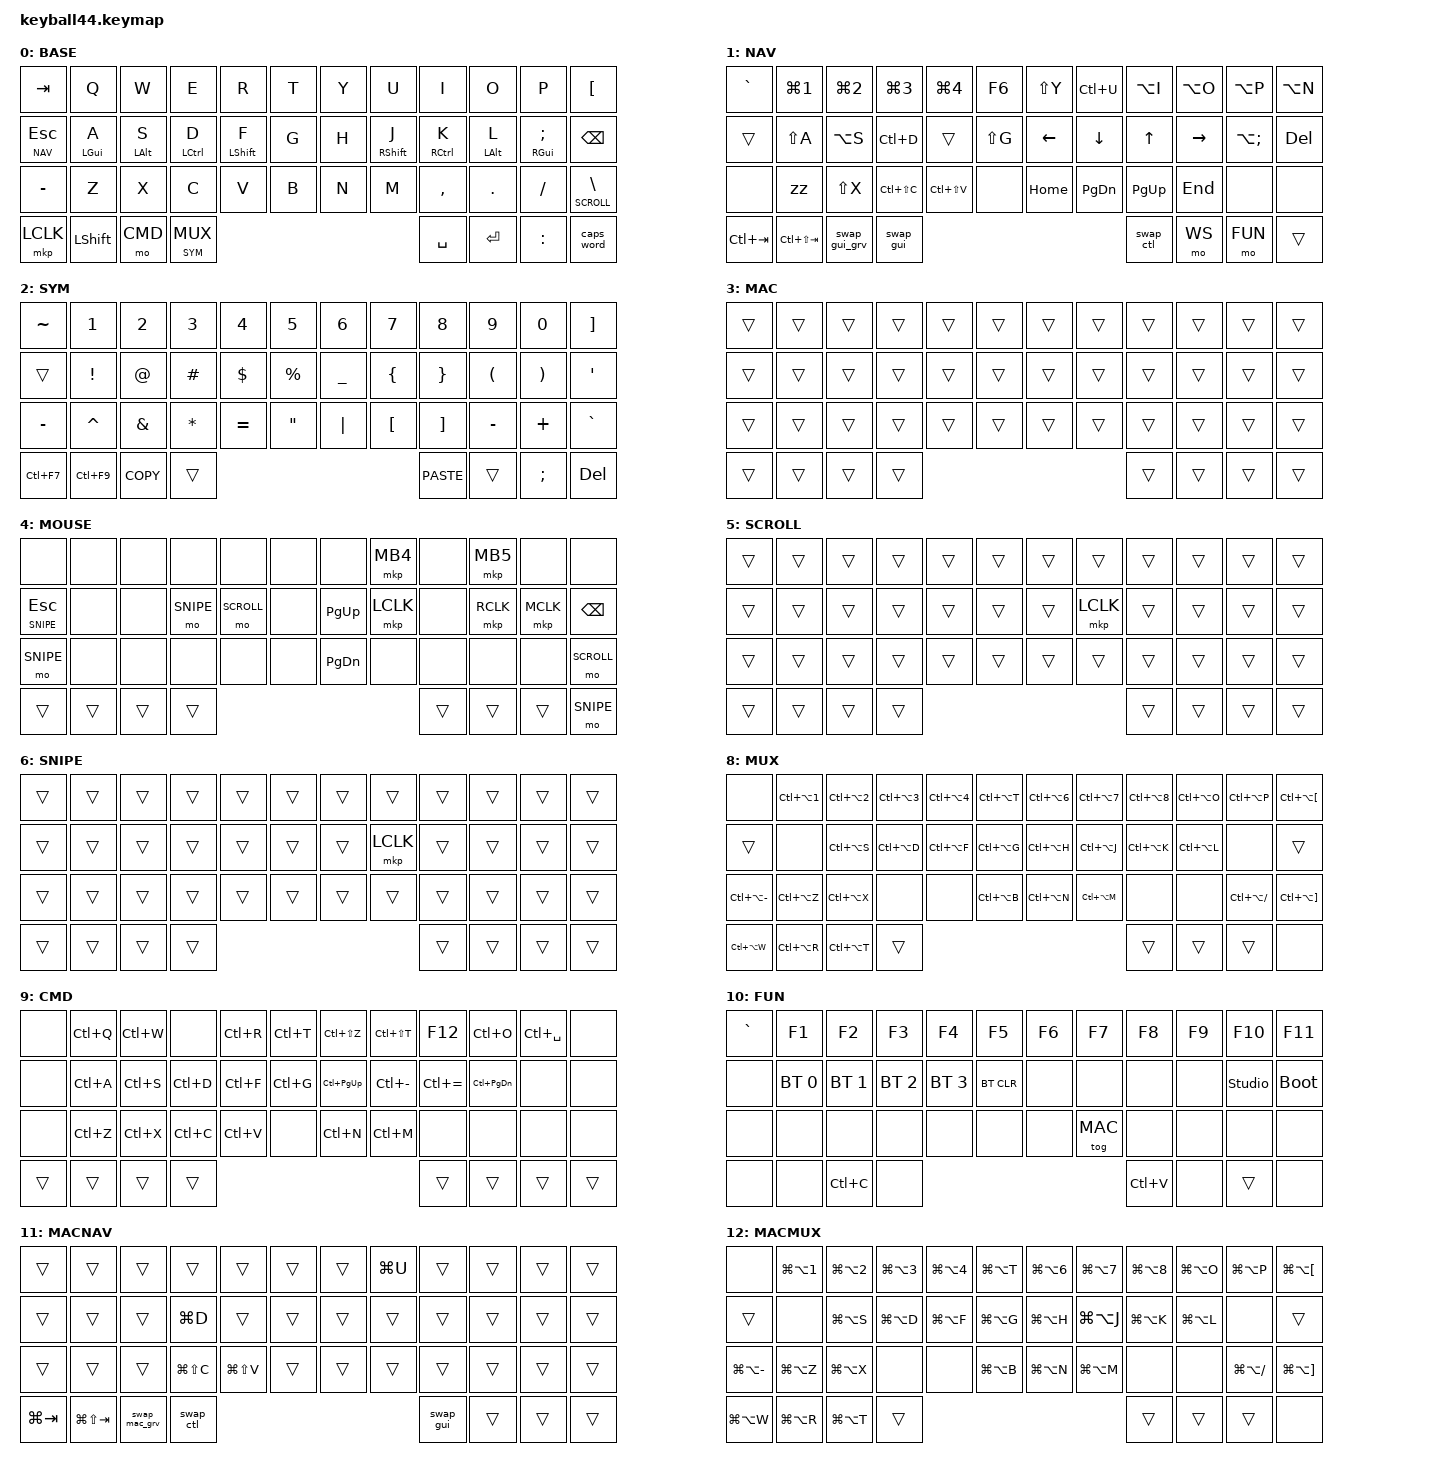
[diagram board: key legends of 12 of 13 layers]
/*
 * Keyball44 — semantic-redesign branch (mac-anchored).
 *
 * Shared with Cornix: homerow mods, sym_mux thumb (hold = SYM, tap =
 * sticky MUX, tap-then-hold = held MUX), zellij MUX layer, helix NAV
 * layer with tri-state swappers.
 *
 * ANCHOR: Linux-truth + macOS per-device modifier swap. macOS System
 * Settings > Keyboard > Modifier Keys (for THIS keyboard only) swaps
 * Ctrl <-> Cmd. Firmware emits Linux-native chords; mac receives Ctrl
 * as Cmd and Gui as Ctrl. Chords holding BOTH Ctrl and Gui are
 * swap-invariant (window quad). Ctrl-chords = command space,
 * Super-chords = window/desktop space.
 *
 * Redesign vs main:
 *   CMD (9)  — semantic command layer on the left thumb (old LCTRL slot):
 *              copy/paste/tab/find etc. as mnemonic Ctrl-chords — native
 *              on KDE, arrive as Cmd-chords on mac via the swap.
 *   WS  (7)  — old DE rebuilt: hjkl = Super+arrows (KDE: bind Meta+arrows
 *              to desktops/overview; mac receives Ctrl+arrows = native
 *              spaces/Mission Control). Window quad swap-invariant.
 *   MAC (3)  — transparent OS flag, toggled via FUN+M (display shows MAC
 *              while idle; NOT persisted across power cycles). Must stay
 *              below MOUSE/SCROLL/SNIPE for the driver's highest-layer
 *              mode detection. Conditional layers MACNAV (11) /
 *              MACMUX (12) re-emit the mac-poisoned chords: real-Ctrl
 *              helix keys, tab cyclers, swappers, zellij grid.
 *   MOUSE    — automouse layer becomes a ball control panel: left hand
 *              gets SCROLL/SNIPE holds, right hand gets MB4/MB5.
 *
 * Keyball-specific: MOUSE/SCROLL/SNIPE trackball layers (indices 4/5/6
 * are hardcoded in keyball44_right.overlay), lt SCROLL on backslash,
 * mkp LCLK on the bottom-left key.
 *
 * Physical map (matrix positions):
 *   0  1  2  3  4  5   |   6  7  8  9 10 11
 *  12 13 14 15 16 17   |  18 19 20 21 22 23
 *  24 25 26 27 28 29   |  30 31 32 33 34 35
 *  36 37 38  39 40     |  41 42          43
 *  (38-40 / 41-42 = thumbs, 36-37 = left extras, 43 = right palm)
 */

#define BASE    0
#define NAV     1
#define SYM     2
#define MAC     3
#define MOUSE   4
#define SCROLL  5
#define SNIPE   6
#define WS      7
#define MUX     8
#define CMD     9
#define FUN     10
#define MACNAV  11
#define MACMUX  12
/* MAC must sit BELOW the trackball layers: the pmw3610 driver detects
 * scroll/snipe (and shows the layer name) via the HIGHEST active layer,
 * so an always-on flag above 4/5/6 would break CPI switching. */

#include <behaviors/mouse_keys.dtsi>
#include <dt-bindings/zmk/mouse.h>
#include <behaviors.dtsi>
#include <dt-bindings/zmk/bt.h>
#include <dt-bindings/zmk/keys.h>
#include <dt-bindings/zmk/pointing.h>

// homerow mods: balanced flavor = permissive hold — a nested tap of ANY
// key (same hand included) resolves the mod instantly on its release.
// No positional hold-trigger restriction, per user preference (Vial feel).
#define HM_TAPPING_TERM 200
#define HM_TAPPING_TERM_FAST 200
#define HM_PRIOR_IDLE 70

&lt {
    flavor = "hold-preferred";
    tapping-term-ms = <HM_TAPPING_TERM>;
    quick-tap-ms = <200>;
};

&caps_word { continue-list = <UNDERSCORE MINUS>; };

// sticky MUX arm window: a tap of sym_mux waits this long for the zellij
// key before dropping. Short on purpose — limits stray-tap damage.
&sl { release-after-ms = <1000>; };

// helix "zz" — center view on cursor
/ {
    macros {
        zz: zz {
            compatible = "zmk,behavior-macro";
            #binding-cells = <0>;
            wait-ms = <20>;
            tap-ms = <20>;
            bindings = <&kp Z &kp Z>;
        };
    };
};

/* Window / app / tab switchers (tri-state module, urob/zmk-tri-state).
 *   swap_gui_grv = Cmd+`   -> cycle windows of the focused app
 *   swap_gui     = Cmd+Tab -> switch apps
 *   swap_ctl     = Ctrl+Tab -> cycle tabs within the app
 * First tap: press+hold mod, send the key. Further taps: key only.
 * The NAV hold IS the mod hold: position 12 (the lt NAV key) is deliberately
 * NOT in ignored-key-positions, so releasing it commits the switcher.
 * Arrows (18-21) don't interrupt, so you can steer the switcher with
 * hjkl-arrows while holding NAV. Same positions as on the Cornix.
 */
/ {
    behaviors {
        swap_gui: swap_gui {
            compatible = "zmk,behavior-tri-state";
            #binding-cells = <0>;
            bindings = <&kt LGUI>, <&kp TAB>, <&kt LGUI>;
            ignored-key-positions = <18 19 20 21>;
        };

        swap_gui_grv: swap_gui_grv {
            compatible = "zmk,behavior-tri-state";
            #binding-cells = <0>;
            bindings = <&kt LGUI>, <&kp GRAVE>, <&kt LGUI>;
            ignored-key-positions = <18 19 20 21>;
        };

        swap_ctl: swap_ctl {
            compatible = "zmk,behavior-tri-state";
            #binding-cells = <0>;
            bindings = <&kt LCTRL>, <&kp TAB>, <&kt LCTRL>;
            ignored-key-positions = <18 19 20 21>;
        };

        /* MAC-mode window cycler: Ctrl+` emission arrives as Cmd+` via
         * the device swap. (App/tab switchers need no new behaviors —
         * on MACNAV, swap_ctl serves as the app switcher (Ctrl+Tab ->
         * Cmd+Tab) and swap_gui as the in-app tab cycler (Gui+Tab ->
         * Ctrl+Tab): the existing tri-states, cross-assigned.) */
        swap_mac_grv: swap_mac_grv {
            compatible = "zmk,behavior-tri-state";
            #binding-cells = <0>;
            bindings = <&kt LCTRL>, <&kp GRAVE>, <&kt LCTRL>;
            ignored-key-positions = <18 19 20 21>;
        };

        hm_l: homerow_mods_left {
            compatible = "zmk,behavior-hold-tap";
            #binding-cells = <2>;
            bindings = <&kp>, <&kp>;
            flavor = "balanced";
            tapping-term-ms = <HM_TAPPING_TERM>;
            quick-tap-ms = <200>;
            require-prior-idle-ms = <HM_PRIOR_IDLE>;
        };

        hm_r: homerow_mods_right {
            compatible = "zmk,behavior-hold-tap";
            #binding-cells = <2>;
            bindings = <&kp>, <&kp>;
            flavor = "balanced";
            tapping-term-ms = <HM_TAPPING_TERM>;
            quick-tap-ms = <200>;
            require-prior-idle-ms = <HM_PRIOR_IDLE>;
        };

        hm_shift_l: hm_shift_l {
            compatible = "zmk,behavior-hold-tap";
            #binding-cells = <2>;
            bindings = <&kp>, <&kp>;
            flavor = "balanced";
            tapping-term-ms = <HM_TAPPING_TERM_FAST>;
            quick-tap-ms = <200>;
            require-prior-idle-ms = <HM_PRIOR_IDLE>;
        };

        hm_shift_r: hm_shift_r {
            compatible = "zmk,behavior-hold-tap";
            #binding-cells = <2>;
            bindings = <&kp>, <&kp>;
            flavor = "balanced";
            tapping-term-ms = <HM_TAPPING_TERM_FAST>;
            quick-tap-ms = <200>;
            require-prior-idle-ms = <HM_PRIOR_IDLE>;
        };

        // hold = SYM, tap = sticky MUX (next key goes to zellij),
        // tap-then-hold = held MUX via quick-tap (the old vial gesture
        // still works). Sticky arm expires via &sl release-after-ms.
        sym_mux: sym_mux {
            compatible = "zmk,behavior-hold-tap";
            #binding-cells = <2>;
            bindings = <&mo>, <&sl>;
            flavor = "hold-preferred";
            tapping-term-ms = <200>;
            quick-tap-ms = <200>;
        };
    };

    conditional_layers {
        compatible = "zmk,conditional-layers";
        macnav {
            if-layers = <MAC NAV>;
            then-layer = <MACNAV>;
        };
        macmux {
            if-layers = <MAC MUX>;
            then-layer = <MACMUX>;
        };
    };

    keymap {
        compatible = "zmk,keymap";

        base_layer {
            label = "BASE";
            //  tab   q    w    e    r    t    |   y    u    i    o    p    [
            //  esc/N a/G  s/A  d/C  f/S  g    |   h    j/S  k/C  l/A  ;/G  bspc
            //  -     z    x    c    v    b    |   n    m    ,    .    /    bsl/SCRL
            //  mb1  shft CMD  SYM* spc        |  ret  :              capsw
            // (thumb LCTRL replaced by CMD hold — raw Ctrl chords go
            //  cross-hand via HRM K; frequent commands live on CMD)
            bindings = <
&kp TAB      &kp Q         &kp W         &kp E          &kp R                &kp T                 &kp Y    &kp U                &kp I          &kp O         &kp P            &kp LBKT
&lt NAV ESC  &hm_l LGUI A  &hm_l LALT S  &hm_l LCTRL D  &hm_shift_l LSHFT F  &kp G                 &kp H    &hm_shift_r RSHFT J  &hm_r RCTRL K  &hm_r LALT L  &hm_r RGUI SEMI  &kp BSPC
&kp MINUS    &kp Z         &kp X         &kp C          &kp V                &kp B                 &kp N    &kp M                &kp COMMA      &kp DOT       &kp FSLH         &lt SCROLL BSLH
&mkp LCLK    &kp LSHFT     &mo CMD       &sym_mux SYM MUX  &kp SPACE                    &kp RET    &kp COLON                                                                   &caps_word
            >;
        };

        nav_layer {
            label = "NAV";
            // helix support + navigation + swappers
            //  `    ws1  ws2  ws3  ws4   F6   |  S-Y  C-u  A-i  A-o  A-p  A-n
            //  __   S-A  A-s  C-d (shft) S-G  |   ←    ↓    ↑    →   A-;  del
            //  __   zz   S-X  tgC  tgV   __   |  Home PgDn PgUp  End  __   __
            //  C-tb CS-tb ⌘`  ⌘tab ^tab       |   DE   FN             __
            bindings = <
&kp GRAVE    &kp LG(N1)       &kp LG(N2)     &kp LG(N3)     &kp LG(N4)     &kp F6                &kp LS(Y)  &kp LC(U)  &kp LA(I)  &kp LA(O)  &kp LA(P)     &kp LA(N)
&trans       &kp LS(A)        &kp LA(S)      &kp LC(D)      &trans         &kp LS(G)             &kp LEFT   &kp DOWN   &kp UP     &kp RIGHT  &kp LA(SEMI)  &kp DEL
&none        &zz              &kp LS(X)      &kp LC(LS(C))  &kp LC(LS(V))  &none                 &kp HOME   &kp PG_DN  &kp PG_UP  &kp END    &none         &none
&kp LC(TAB)  &kp LC(LS(TAB))  &swap_gui_grv  &swap_gui      &swap_ctl                 &mo WS     &mo FUN                                                   &trans
            >;
        };

        symbol_layer {
            label = "SYM";
            //  ~     1    2    3    4    5    |   6    7    8    9    0    ]
            //  __    !    @    #    $    %    |   _    {    }    (    )    '
            //  -     ^    &    *    =    "    |   |    [    ]    -    +    `
            //  cF7  cF9  copy  __  paste      |   __   ;              del
            //  (bottom-right = plain GRAVE, was a duplicate of base \ :
            //   backtick in English; in Ukrainian the unshifted grave
            //   key is the apostrophe on every OS. Windows maps the
            //   shifted one (our ~ key) to the hryvnia sign instead.)
            //  (cF7 = show windows of same app / App Exposé, cF9 =
            //   Mission Control — stable chords bound on BOTH OSes.
            //   After the mac Ctrl<->Cmd swap they arrive as Cmd+F7/F9:
            //   re-record the two mac Mission Control shortcuts once.)
            bindings = <
&kp TILDE  &kp N1     &kp N2    &kp N3     &kp N4       &kp N5               &kp N6     &kp N7    &kp N8    &kp N9     &kp N0    &kp RBKT
&trans     &kp EXCL   &kp AT    &kp HASH   &kp DLLR     &kp PRCNT            &kp UNDER  &kp LBRC  &kp RBRC  &kp LPAR   &kp RPAR  &kp SQT
&kp MINUS  &kp CARET  &kp AMPS  &kp ASTRK  &kp EQUAL    &kp DQT              &kp PIPE   &kp LBKT  &kp RBKT  &kp MINUS  &kp PLUS  &kp GRAVE
&kp LC(F7) &kp LC(F9) &kp K_COPY &trans    &kp K_PASTE             &trans    &kp SEMI                                            &kp DEL
            >;
        };

        mac_layer {
            label = "MAC";
            // transparent OS flag (layer 3) — drives the MACNAV/MACMUX
            // conditional layers and the pointer scaler. Toggled FUN+M.
            // Deliberately BELOW MOUSE/SCROLL/SNIPE so the driver's
            // highest-layer checks still see them (snipe/scroll CPI).
            bindings = <
&trans  &trans  &trans  &trans  &trans  &trans              &trans  &trans  &trans  &trans  &trans  &trans
&trans  &trans  &trans  &trans  &trans  &trans              &trans  &trans  &trans  &trans  &trans  &trans
&trans  &trans  &trans  &trans  &trans  &trans              &trans  &trans  &trans  &trans  &trans  &trans
&trans  &trans  &trans  &trans  &trans              &trans  &trans                                  &trans
            >;
        };

        mouse_layer {
            label = "MOUSE";
            // ball control panel: automouse arms the left hand —
            // F = scroll hold, D = snipe hold (opposite hand from the
            // ball, no pinky curl). Thumb shift/CMD stay transparent for
            // shift-click and copy/paste while mousing. MB4/MB5 =
            // browser back/forward on U/O.
            bindings = <
&none            &none  &none  &none        &none        &none              &none          &mkp MB4   &none   &mkp MB5   &none      &none
&lt SNIPE ESCAPE &none  &none  &mo SNIPE    &mo SCROLL   &none              &kp PAGE_UP    &mkp LCLK  &none   &mkp RCLK  &mkp MCLK  &kp BACKSPACE
&mo SNIPE        &none  &none  &none        &none        &none              &kp PAGE_DOWN  &none      &none   &none      &none      &mo SCROLL
&trans           &trans &trans &trans       &trans                &trans    &trans                                                  &mo SNIPE
            >;
        };

        scroll_layer {
            label = "SCROLL";
            bindings = <
&trans  &trans  &trans  &trans  &trans  &trans              &trans  &trans     &trans  &trans  &trans  &trans
&trans  &trans  &trans  &trans  &trans  &trans              &trans  &mkp LCLK  &trans  &trans  &trans  &trans
&trans  &trans  &trans  &trans  &trans  &trans              &trans  &trans     &trans  &trans  &trans  &trans
&trans  &trans  &trans  &trans  &trans              &trans  &trans                                     &trans
            >;
        };

        snipe_layer {
            label = "SNIPE";
            bindings = <
&trans  &trans  &trans  &trans  &trans  &trans              &trans  &trans     &trans  &trans  &trans  &trans
&trans  &trans  &trans  &trans  &trans  &trans              &trans  &mkp LCLK  &trans  &trans  &trans  &trans
&trans  &trans  &trans  &trans  &trans  &trans              &trans  &trans     &trans  &trans  &trans  &trans
&trans  &trans  &trans  &trans  &trans              &trans  &trans                                     &trans
            >;
        };

        ws_layer {
            label = "WS";
            // spatial layer: "NAV moves the cursor, WS moves containers".
            // hjkl home row = Super+arrows on the same positions as the
            // NAV arrows. KDE: bind Meta+Left/Right to desktops,
            // Meta+Up/Down to overview/grid. mac: the swap turns them
            // into Ctrl+arrows = native spaces / Mission Control /
            // App Exposé — relative, survives dynamic space numbering.
            // Row above = old DE window quad (Cmd+Ctrl+arrows) —
            // swap-invariant, identical on both OSes.
            // Old DE parked Cmd+arrow trio deleted: under the swap its
            // emissions became identical to the hjkl natives.
            // Left half = old DE, untouched.
            bindings = <
&none   &kp LA(F4)        &kp LC(F8)         &kp LG(E)          &none           &none                     &none         &kp LG(LC(LEFT))      &kp LG(LC(DOWN))  &kp LG(LC(UP))         &kp LG(LC(RIGHT))  &none
&none   &kp LC(F7)        &kp LC(F9)         &kp LG(D)          &kp LC(F10)     &none                     &kp LG(LEFT)  &kp LG(DOWN)          &kp LG(UP)        &kp LG(RIGHT)          &none              &none
&none   &kp LC(LA(LEFT))  &kp LC(LA(RIGHT))  &kp LC(LA(DOWN))   &kp LC(LA(UP))  &none                     &none         &kp LC(LA(LS(LEFT))) &none             &kp LC(LA(LS(RIGHT)))  &none              &none
&trans  &trans            &trans             &trans             &trans                              &trans  &trans                                                                                      &trans
            >;
        };

        mux_layer {
            label = "MUX";
            // zellij: everything sends Ctrl+Alt+<key>; see zellij config.kdl
            //  __   ca1  ca2  ca3  ca4  caT   |  ca6  ca7  ca8  caO  caP  ca[
            //  __    __  caS  caD  caF  caG   |  caH  caJ  caK  caL   __   __
            //  ca-  caZ  caX   __   __  caB   |  caN  caM   __   __  ca/  ca]
            //  caW  caR  caT   __   __        |   __   __             __
            bindings = <
&none              &kp LC(LA(N1))  &kp LC(LA(N2))  &kp LC(LA(N3))  &kp LC(LA(N4))  &kp LC(LA(T))                &kp LC(LA(N6))  &kp LC(LA(N7))  &kp LC(LA(N8))  &kp LC(LA(O))  &kp LC(LA(P))     &kp LC(LA(LBKT))
&trans             &none           &kp LC(LA(S))   &kp LC(LA(D))   &kp LC(LA(F))   &kp LC(LA(G))                &kp LC(LA(H))   &kp LC(LA(J))   &kp LC(LA(K))   &kp LC(LA(L))  &none             &trans
&kp LC(LA(MINUS))  &kp LC(LA(Z))   &kp LC(LA(X))   &none           &none           &kp LC(LA(B))                &kp LC(LA(N))   &kp LC(LA(M))   &none           &none          &kp LC(LA(FSLH))  &kp LC(LA(RBKT))
&kp LC(LA(W))      &kp LC(LA(R))   &kp LC(LA(T))   &trans          &trans                        &trans         &trans                                                                           &none
            >;
        };

        cmd_layer {
            label = "CMD";
            // semantic OS commands as Ctrl-chords: native on Linux,
            // arrive as Cmd-chords on mac via the device swap. One
            // intent per key, mnemonic, left-hand-first so the whole
            // edit workflow is one-handed while the ball hand mouses.
            // Inspect = F12 (universal). Tab prev/next = Ctrl+PgUp/PgDn
            // (Linux-native; mac: bind Show Prev/Next Tab in App
            // Shortcuts to Cmd+PgUp/PgDn once).
            //  __  quit clos __  reld ntab | redo reop insp open laun __
            //  __  sall save bkmk find fnxt| tab← zo-  zo+  tab→  __  __
            //  __  undo cut  copy pste __  | nwin mini  __   __   __  __
            //  __   __   __   __   __      |  __   __             __
            bindings = <
&none   &kp LC(Q)  &kp LC(W)  &none      &kp LC(R)  &kp LC(T)              &kp LC(LS(Z))     &kp LC(LS(T))  &kp F12        &kp LC(O)         &kp LC(SPACE)  &none
&none   &kp LC(A)  &kp LC(S)  &kp LC(D)  &kp LC(F)  &kp LC(G)              &kp LC(PG_UP)     &kp LC(MINUS)  &kp LC(EQUAL)  &kp LC(PG_DN)     &none          &none
&none   &kp LC(Z)  &kp LC(X)  &kp LC(C)  &kp LC(V)  &none                  &kp LC(N)         &kp LC(M)      &none          &none             &none          &none
&trans  &trans     &trans     &trans     &trans                   &trans   &trans                                                                            &trans
            >;
        };

        function_layer {
            label = "FUN";
            //  `     F1   F2   F3   F4   F5   |   F6   F7   F8   F9   F10  F11
            //  __   bt0  bt1  bt2  bt3  btclr |   __   __   __   __  studio boot
            //  __    __   __   __   __   __   |   __  MAC!  __   __   __   __
            //  __    __   ^C   __   ^V        |   __   __             __
            // MAC! = &tog MAC (M for mac) — OS mode flag; display shows
            // "MAC" while idle. Not persisted: retoggle after power cycle.
            bindings = <
&kp GRAVE  &kp F1        &kp F2        &kp F3        &kp F4        &kp F5                &kp F6  &kp F7    &kp F8  &kp F9  &kp F10         &kp F11
&none      &bt BT_SEL 0  &bt BT_SEL 1  &bt BT_SEL 2  &bt BT_SEL 3  &bt BT_CLR            &none   &none     &none   &none   &studio_unlock  &bootloader
&none      &none         &none         &none         &none         &none                 &none   &tog MAC  &none   &none   &none           &none
&none      &none         &kp LC(C)     &none         &kp LC(V)                 &none     &trans                                          &none
            >;
        };

        macnav_layer {
            label = "MACNAV";
            // active when MAC && NAV: re-emits the mac-poisoned NAV keys.
            // Real-Ctrl helix keys emit Gui (arrives as Ctrl via swap);
            // tab cyclers likewise; swappers cross-assigned: swap_mac_grv
            // = Cmd+` window cycle, swap_ctl = Cmd+Tab app switcher,
            // swap_gui = Ctrl+Tab in-app tabs. Everything else falls
            // through to NAV.
            bindings = <
&trans       &trans           &trans         &trans          &trans          &trans                &trans  &kp LG(U)  &trans  &trans  &trans  &trans
&trans       &trans           &trans         &kp LG(D)       &trans          &trans                &trans  &trans     &trans  &trans  &trans  &trans
&trans       &trans           &trans         &kp LG(LS(C))   &kp LG(LS(V))   &trans                &trans  &trans     &trans  &trans  &trans  &trans
&kp LG(TAB)  &kp LG(LS(TAB))  &swap_mac_grv  &swap_ctl       &swap_gui                   &trans    &trans                                     &trans
            >;
        };

        macmux_layer {
            label = "MACMUX";
            // active when MAC && MUX: the zellij grid re-emitted as
            // Gui+Alt so the swap delivers Ctrl+Alt — zellij config
            // stays identical on both OSes.
            bindings = <
&none              &kp LG(LA(N1))  &kp LG(LA(N2))  &kp LG(LA(N3))  &kp LG(LA(N4))  &kp LG(LA(T))                &kp LG(LA(N6))  &kp LG(LA(N7))  &kp LG(LA(N8))  &kp LG(LA(O))  &kp LG(LA(P))     &kp LG(LA(LBKT))
&trans             &none           &kp LG(LA(S))   &kp LG(LA(D))   &kp LG(LA(F))   &kp LG(LA(G))                &kp LG(LA(H))   &kp LG(LA(J))   &kp LG(LA(K))   &kp LG(LA(L))  &none             &trans
&kp LG(LA(MINUS))  &kp LG(LA(Z))   &kp LG(LA(X))   &none           &none           &kp LG(LA(B))                &kp LG(LA(N))   &kp LG(LA(M))   &none           &none          &kp LG(LA(FSLH))  &kp LG(LA(RBKT))
&kp LG(LA(W))      &kp LG(LA(R))   &kp LG(LA(T))   &trans          &trans                        &trans         &trans                                                                           &none
            >;
        };
    };
};
